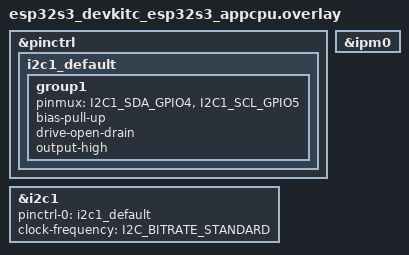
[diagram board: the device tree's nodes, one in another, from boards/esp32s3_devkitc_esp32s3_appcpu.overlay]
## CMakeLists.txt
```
cmake_minimum_required(VERSION 3.20.0)

find_package(Zephyr REQUIRED HINTS $ENV{ZEPHYR_BASE})
project(gy521_mpu6050_appcpu)

target_sources(app PRIVATE
	src/main.c
	src/ssd1306_display.c
)
```

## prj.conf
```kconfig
# 02_GY521_MPU6050 - core1 (appcpu) image
#
# No CONFIG_SENSOR here - this core never touches the MPU6050, only
# the SSD1306 over I2C1 and the IPM mailbox from core0.

CONFIG_I2C=y
CONFIG_GPIO=y

CONFIG_IPM=y
CONFIG_ESP32_SOFT_IPM=y

CONFIG_LOG=y
CONFIG_LOG_MODE_IMMEDIATE=y

CONFIG_FPU=y
```

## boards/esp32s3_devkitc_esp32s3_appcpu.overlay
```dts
/*
 * Overlay for 02_GY521_MPU6050 - core1 (appcpu) image
 *
 * Identical convention to Lab 01: I2C1 (NOT I2C0) at SDA=GPIO4 /
 * SCL=GPIO5, since core1 must own a physically different I2C
 * controller than core0's MPU6050 bus. No sensor devicetree nodes
 * here - core1 never talks to the MPU6050 directly, only to the
 * SSD1306 (probed at runtime by src/ssd1306_display.c).
 */

#include <dt-bindings/pinctrl/esp32s3-pinctrl.h>
#include <zephyr/dt-bindings/i2c/i2c.h>

&pinctrl {
	i2c1_default: i2c1_default {
		group1 {
			pinmux = <I2C1_SDA_GPIO4>, <I2C1_SCL_GPIO5>;
			bias-pull-up;
			drive-open-drain;
			output-high;
		};
	};
};

&i2c1 {
	status = "okay";
	pinctrl-0 = <&i2c1_default>;
	pinctrl-names = "default";
	clock-frequency = <I2C_BITRATE_STANDARD>; /* 100 kHz */
};

&ipm0 {
	status = "okay";
};
```

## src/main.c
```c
/*
 * main.c - 02_GY521_MPU6050 (core1 / appcpu image)
 *
 * Same pattern as Lab 01's core1: receive sensor snapshots from core0
 * over IPM and draw them on the SSD1306. This core never touches I2C0
 * or the MPU6050 - see src/main.c (core0) and the design doc for why
 * the two cores each own a different physical I2C controller.
 *
 * Event flow: the ESP32 IPM driver invokes `ipm_callback()` in
 * interrupt context whenever core0 sends a message. ISR context must
 * stay short and must not do blocking I2C transfers, so the callback
 * only copies the payload into a message queue (k_msgq_put with
 * K_NO_WAIT is ISR-safe) and returns immediately. The actual OLED
 * redraw happens in `display_thread_fn()`, which blocks on
 * `k_msgq_get()` and only wakes when a new sample has actually
 * arrived.
 *
 * core0 pushes immediately when the accel or gyro vector magnitude
 * moves past a threshold since the last value it sent, plus a 1s
 * heartbeat so this side has something to declare "alive" during
 * quiet periods. This side only cares about elapsed time since the
 * last arrival: if nothing shows up in `sensor_msgq` for 2 s, the
 * link is considered down.
 */

#include <zephyr/kernel.h>
#include <zephyr/device.h>
#include <zephyr/drivers/i2c.h>
#include <zephyr/drivers/ipm.h>
#include <zephyr/logging/log.h>
#include <string.h>

#include "ipm_protocol.h"
#include "ssd1306_display.h"

LOG_MODULE_REGISTER(app_appcpu, LOG_LEVEL_INF);

static const struct device *dev_i2c1 = DEVICE_DT_GET(DT_NODELABEL(i2c1));
static const struct device *dev_ipm  = DEVICE_DT_GET(DT_NODELABEL(ipm0));

/* Depth 4: core0 sends at most every 100 ms in the busiest case
 * (constant motion), so this just needs enough slack to absorb a
 * brief scheduling delay on the display thread.
 */
K_MSGQ_DEFINE(sensor_msgq, sizeof(struct ipm_sensor_payload), 4, 4);

/* Runs in IPM ISR context - keep it minimal. */
static void ipm_callback(const struct device *ipmdev, void *user_data,
			  uint32_t id, volatile void *data)
{
	ARG_UNUSED(ipmdev);
	ARG_UNUSED(user_data);

	if (id != IPM_SENSOR_CHANNEL) {
		return; /* not our channel - ignore */
	}

	struct ipm_sensor_payload payload;

	memcpy(&payload, (const void *)data, sizeof(payload));

	if (k_msgq_put(&sensor_msgq, &payload, K_NO_WAIT) != 0) {
		/* Queue momentarily full - drop the oldest entry and
		 * keep the newest one, since only the latest snapshot is
		 * ever useful for a live display.
		 */
		struct ipm_sensor_payload discard;

		k_msgq_get(&sensor_msgq, &discard, K_NO_WAIT);
		k_msgq_put(&sensor_msgq, &payload, K_NO_WAIT);
	}
}

static void format_fixed(float value, int decimals, char *buf, size_t buf_len)
{
	bool negative = value < 0.0f;
	float abs_value = negative ? -value : value;
	int scale = (decimals == 2) ? 100 : 10;
	int scaled = (int)(abs_value * scale + 0.5f);

	if (decimals == 2) {
		snprintf(buf, buf_len, "%s%d.%02d", negative ? "-" : "",
			  scaled / scale, scaled % scale);
	} else {
		snprintf(buf, buf_len, "%s%d.%d", negative ? "-" : "",
			  scaled / scale, scaled % scale);
	}
}

static void render_payload(const struct ipm_sensor_payload *p, bool stale)
{
	char line[22];
	char num[10];

	ssd1306_clear();

	/* Link health goes first/top - it qualifies how much to trust
	 * everything else on the screen.
	 */
	ssd1306_draw_text(0, 0, stale ? "LINK: FAIL" : "LINK: OK");

	if (p->valid) {
		format_fixed(p->accel_x_g, 2, num, sizeof(num));
		snprintf(line, sizeof(line), "AX:%s", num);
		ssd1306_draw_text(1, 0, line);

		format_fixed(p->accel_y_g, 2, num, sizeof(num));
		snprintf(line, sizeof(line), "AY:%s", num);
		ssd1306_draw_text(2, 0, line);

		format_fixed(p->accel_z_g, 2, num, sizeof(num));
		snprintf(line, sizeof(line), "AZ:%s", num);
		ssd1306_draw_text(3, 0, line);

		format_fixed(p->gyro_x_dps, 1, num, sizeof(num));
		snprintf(line, sizeof(line), "GX:%s", num);
		ssd1306_draw_text(4, 0, line);

		format_fixed(p->gyro_y_dps, 1, num, sizeof(num));
		snprintf(line, sizeof(line), "GY:%s", num);
		ssd1306_draw_text(5, 0, line);

		format_fixed(p->gyro_z_dps, 1, num, sizeof(num));
		snprintf(line, sizeof(line), "GZ:%s", num);
		ssd1306_draw_text(6, 0, line);

		format_fixed(p->temp_c, 1, num, sizeof(num));
		snprintf(line, sizeof(line), "TEMP:%sC", num);
		ssd1306_draw_text(7, 0, line);
	} else {
		ssd1306_draw_text(3, 0, "MPU6050 ---");
	}

	ssd1306_flush();
}

static void display_thread_fn(void *p1, void *p2, void *p3)
{
	ARG_UNUSED(p1);
	ARG_UNUSED(p2);
	ARG_UNUSED(p3);

	int ret = ssd1306_display_init(dev_i2c1);

	if (ret) {
		LOG_ERR("SSD1306 init failed: %d - display thread exiting", ret);
		return;
	}

	ssd1306_draw_text(3, 0, "WAITING FOR");
	ssd1306_draw_text(4, 0, "CORE0...");
	ssd1306_flush();

	bool have_data = false;
	struct ipm_sensor_payload last_payload = { 0 };

	while (1) {
		struct ipm_sensor_payload payload;
		/* core0's heartbeat alone guarantees a message at least
		 * every 1 s even with no motion, so 2000 ms of total
		 * silence means something upstream stalled (sensor
		 * thread stuck, IPM channel jammed, core0 crashed, etc)
		 * rather than just "nothing moved".
		 */
		int ret2 = k_msgq_get(&sensor_msgq, &payload, K_MSEC(2000));

		if (ret2 == 0) {
			last_payload = payload;
			have_data = true;
			render_payload(&last_payload, false);
		} else if (have_data) {
			render_payload(&last_payload, true);
		}
		/* else: never received anything yet - keep showing the
		 * "WAITING FOR CORE0..." screen drawn above.
		 */
	}
}

K_THREAD_DEFINE(display_tid, 2048, display_thread_fn, NULL, NULL, NULL, 6, 0, 0);

int main(void)
{
	LOG_INF("02_GY521_MPU6050 (core1/appcpu) starting");

	if (!device_is_ready(dev_i2c1)) {
		LOG_ERR("I2C1 bus not ready");
		return -1;
	}
	if (!device_is_ready(dev_ipm)) {
		LOG_ERR("IPM device not ready - cannot receive sensor data from core0");
		return -1;
	}

	ipm_register_callback(dev_ipm, ipm_callback, NULL);
	ipm_set_enabled(dev_ipm, 1);

	/* display_thread_fn is already running (K_THREAD_DEFINE, 0 delay). */
	return 0;
}
```
